# STM32H7B0x register map
File version: 1.3
CPU: CM7 r0p1, little endian, MPU, FPU, 4 interrupt priority bits
Registers are 32-bit, read-write, reset 0x0 unless marked. A register's access mark holds for its fields unless they carry their own. Offsets are from the block's base; [hi:lo] are bit positions; 'fields as' and 'values as' point back to an identical list.

## RTC
Base 0x58004000
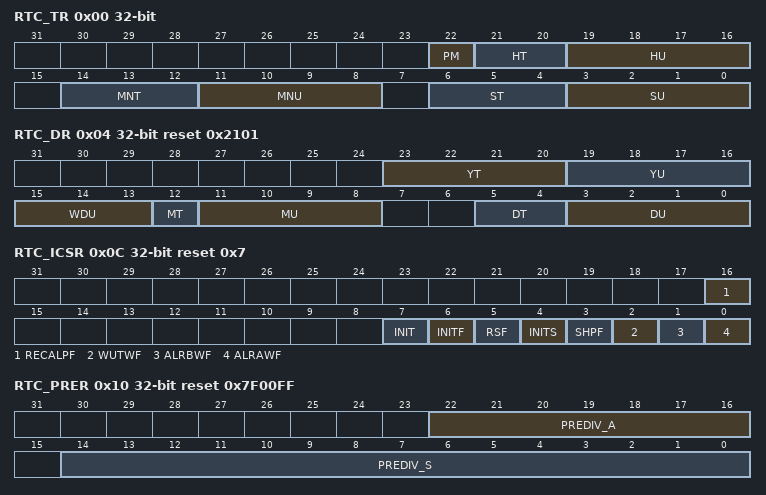
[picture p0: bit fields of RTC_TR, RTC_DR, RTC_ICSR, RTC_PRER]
0x00 RTC_TR — RTC time register
  [22] PM — AM/PM notation
    0=AM or 24-hour format; 1=PM
  [21:20] HT — Hour tens in BCD format
  [19:16] HU — Hour units in BCD format
  [14:12] MNT — Minute tens in BCD format
  [11:8] MNU — Minute units in BCD format
  [6:4] ST — Second tens in BCD format
  [3:0] SU — Second units in BCD format
0x04 RTC_DR reset 0x2101 — RTC date register
  [23:20] YT — Year tens in BCD format
  [19:16] YU — Year units in BCD format
  [15:13] WDU — Week day units ...
    0=forbidden; 1=Monday; 7=Sunday
  [12] MT — Month tens in BCD format
  [11:8] MU — Month units in BCD format
  [5:4] DT — Date tens in BCD format
  [3:0] DU — Date units in BCD format
0x08 RTC_SSR ro — RTC sub second register
  [15:0] SS — Sub second value SS[15:0] is the value in the synchronous prescaler counter. The fraction of a second is given by the formula below: Second fraction = (PREDIV_S - SS) / (PREDIV_S + 1) Note: SS can be larger than PREDIV_S only after a shift operation. In that case, the correct time/date is one second less than as indicated by RTC_TR/RTC_DR.
0x0C RTC_ICSR access per field reset 0x7 — RTC initialization control and status register
  [16] RECALPF ro — Recalibration pending Flag The RECALPF status flag is automatically set to 1 when software writes to the RTC_CALR register, indicating that the RTC_CALR register is blocked. When the new calibration settings are taken into account, this bit returns to 0. Refer to .
  [7] INIT rw — Initialization mode
    0=Free running mode; 1=Initialization mode used to program time and date register (RTC_TR and RTC_DR), and prescaler register (RTC_PRER). Counters are stopped and start counting from the new value when INIT is reset.
  [6] INITF ro — Initialization flag When this bit is set to 1, the RTC is in initialization state, and the time, date and prescaler registers can be updated.
    0=Calendar registers update is not allowed; 1=Calendar registers update is allowed
  [5] RSF rw — Registers synchronization flag This bit is set by hardware each time the calendar registers are copied into the shadow registers (RTC_SSRx, RTC_TRx and RTC_DRx). This bit is cleared by hardware in initialization mode, while a shift operation is pending (SHPF = 1), or when in bypass shadow register mode (BYPSHAD = 1). This bit can also be cleared by software. It is cleared either by software or by hardware in initialization mode.
    0=Calendar shadow registers not yet synchronized; 1=Calendar shadow registers synchronized
  [4] INITS ro — Initialization status flag This bit is set by hardware when the calendar year field is different from 0 (Backup domain reset state).
    0=Calendar has not been initialized; 1=Calendar has been initialized
  [3] SHPF ro — Shift operation pending This flag is set by hardware as soon as a shift operation is initiated by a write to the RTC_SHIFTR register. It is cleared by hardware when the corresponding shift operation has been executed. Writing to the SHPF bit has no effect.
    0=No shift operation is pending; 1=A shift operation is pending
  [2] WUTWF ro — Wakeup timer write flag This bit is set by hardware when WUT value can be changed, after the WUTE bit has been set to 0 in RTC_CR. It is cleared by hardware in initialization mode.
    0=Wakeup timer configuration update not allowed except in initialization mode; 1=Wakeup timer configuration update allowed
  [1] ALRBWF ro — Alarm B write flag This bit is set by hardware when alarm B values can be changed, after the ALRBE bit has been set to 0 in RTC_CR. It is cleared by hardware in initialization mode.
    0=Alarm B update not allowed; 1=Alarm B update allowed
  [0] ALRAWF ro — Alarm A write flag This bit is set by hardware when alarm A values can be changed, after the ALRAE bit has been set to 0 in RTC_CR. It is cleared by hardware in initialization mode.
    0=Alarm A update not allowed; 1=Alarm A update allowed
0x10 RTC_PRER reset 0x7F00FF — RTC prescaler register
  [22:16] PREDIV_A — Asynchronous prescaler factor This is the asynchronous division factor: ck_apre frequency = RTCCLK frequency/(PREDIV_A+1)
  [14:0] PREDIV_S — Synchronous prescaler factor This is the synchronous division factor: ck_spre frequency = ck_apre frequency/(PREDIV_S+1)
0x14 RTC_WUTR reset 0xFFFF — RTC wakeup timer register
  [15:0] WUT — Wakeup auto-reload value bits When the wakeup timer is enabled (WUTE set to 1), the WUTF flag is set every (WUT[15:0]Â +Â 1) ck_wut cycles. The ck_wut period is selected through WUCKSEL[2:0] bits of the RTC_CR register. When WUCKSEL[2] = 1, the wakeup timer becomes 17-bits and WUCKSEL[1] effectively becomes WUT[16] the most-significant bit to be reloaded into the timer. The first assertion of WUTF occurs between WUT and (WUT + 1) ck_wut cycles after WUTE is set. Setting WUT[15:0] to 0x0000 with WUCKSEL[2:0] = 011 (RTCCLK/2) is forbidden.
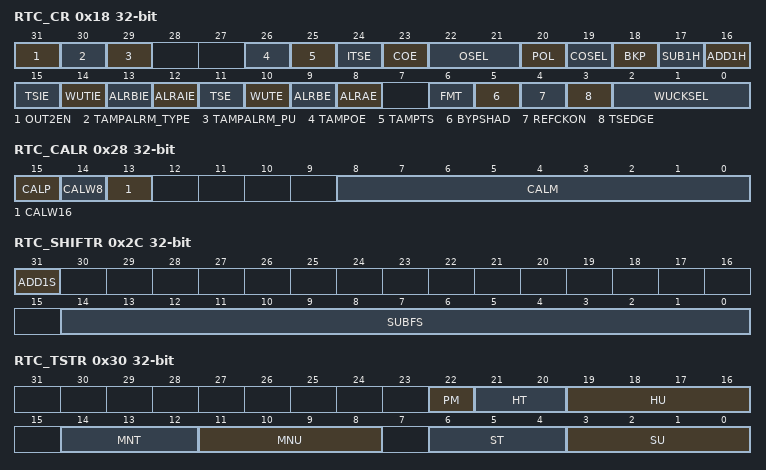
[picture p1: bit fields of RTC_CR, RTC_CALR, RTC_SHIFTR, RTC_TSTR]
0x18 RTC_CR access per field — RTC control register
  [31] OUT2EN rw — RTC_OUT2 output enable Setting this bit allows to remap the RTC outputs on RTC_OUT2 as follows: OUT2EN = 0: RTC output 2 disable If OSEL â 00 or TAMPOE = 1: TAMPALRM is output on RTC_OUT1 If OSEL = 00 and TAMPOE = 0 and COE = 1: CALIB is output on RTC_OUT1 OUT2EN = 1: RTC output 2 enable If (OSEL â 00 or TAMPOE = 1) and COE = 0: TAMPALRM is output on RTC_OUT2 If OSEL = 00 and TAMPOE = 0 and COE = 1: CALIB is output on RTC_OUT2 If (OSELâ 00 or TAMPOE = 1) and COE = 1: CALIB is output on RTC_OUT2 and TAMPALRM is output on RTC_OUT1.
  [30] TAMPALRM_TYPE rw — TAMPALRM output type
    0=TAMPALRM is push-pull output; 1=TAMPALRM is open-drain output
  [29] TAMPALRM_PU rw — TAMPALRM pull-up enable
    0=No pull-up is applied on TAMPALRM output; 1=A pull-up is applied on TAMPALRM output
  [26] TAMPOE rw — Tamper detection output enable on TAMPALRM
    0=The tamper flag is not routed on TAMPALRM; 1=The tamper flag is routed on TAMPALRM, combined with the signal provided by OSEL and with the polarity provided by POL
  [25] TAMPTS rw — Activate timestamp on tamper detection event TAMPTS is valid even if TSE = 0 in the RTC_CR register. Timestamp flag is set after the tamper flags, therefore if TAMPTS and TSIE are set, it is recommended to disable the tamper interrupts in order to avoid servicing 2 interrupts.
    0=Tamper detection event does not cause a RTC timestamp to be saved; 1=Save RTC timestamp on tamper detection event
  [24] ITSE rw — timestamp on internal event enable
    0=internal event timestamp disabled; 1=internal event timestamp enabled
  [23] COE rw — Calibration output enable This bit enables the CALIB output
    0=Calibration output disabled; 1=Calibration output enabled
  [22:21] OSEL rw — Output selection These bits are used to select the flag to be routed to TAMPALRM output.
    0=Output disabled; 1=Alarm A output enabled; 2=Alarm B output enabled; 3=Wakeup output enabled
  [20] POL rw — Output polarity This bit is used to configure the polarity of TAMPALRM output.
    0=The pin is high when ALRAF/ALRBF/WUTF is asserted (depending on OSEL[1:0]), or when a TAMPxF/ITAMPxF is asserted (if TAMPOE = 1); 1=The pin is low when ALRAF/ALRBF/WUTF is asserted (depending on OSEL[1:0]), or when a TAMPxF/ITAMPxF is asserted (if TAMPOE = 1)
  [19] COSEL rw — Calibration output selection When COE = 1, this bit selects which signal is output on CALIB. These frequencies are valid for RTCCLK at 32.768Â kHz and prescalers at their default values (PREDIV_A = 127 and PREDIV_S = 255). Refer to .
    0=Calibration output is 512 Hz; 1=Calibration output is 1 Hz
  [18] BKP rw — Backup This bit can be written by the user to memorize whether the daylight saving time change has been performed or not.
  [17] SUB1H wo — Subtract 1 hour (winter time change) When this bit is set outside initialization mode, 1 hour is subtracted to the calendar time if the current hour is not 0. This bit is always read as 0. Setting this bit has no effect when current hour is 0.
    0=No effect; 1=Subtracts 1 hour to the current time. This can be used for winter time change.
  [16] ADD1H wo — Add 1 hour (summer time change) When this bit is set outside initialization mode, 1 hour is added to the calendar time. This bit is always read as 0.
    0=No effect; 1=Adds 1 hour to the current time. This can be used for summer time change
  [15] TSIE rw — Timestamp interrupt enable
    0=Timestamp interrupt disable; 1=Timestamp interrupt enable
  [14] WUTIE rw — Wakeup timer interrupt enable
    0=Wakeup timer interrupt disabled; 1=Wakeup timer interrupt enabled
  [13] ALRBIE rw — Alarm B interrupt enable
    0=Alarm B interrupt disable; 1=Alarm B interrupt enable
  [12] ALRAIE rw — Alarm A interrupt enable
    0=Alarm A interrupt disabled; 1=Alarm A interrupt enabled
  [11] TSE rw — timestamp enable
    0=timestamp disable; 1=timestamp enable
  [10] WUTE rw — Wakeup timer enable Note: When the wakeup timer is disabled, wait for WUTWF=1 before enabling it again.
    0=Wakeup timer disabled; 1=Wakeup timer enabled
  [9] ALRBE rw — Alarm B enable
    0=Alarm B disabled; 1=Alarm B enabled
  [8] ALRAE rw — Alarm A enable
    0=Alarm A disabled; 1=Alarm A enabled
  [6] FMT rw — Hour format
    0=24 hour/day format; 1=AM/PM hour format
  [5] BYPSHAD rw — Bypass the shadow registers Note: If the frequency of the APB1 clock is less than seven times the frequency of RTCCLK, BYPSHAD must be set to 1.
    0=Calendar values (when reading from RTC_SSR, RTC_TR, and RTC_DR) are taken from the shadow registers, which are updated once every two RTCCLK cycles; 1=Calendar values (when reading from RTC_SSR, RTC_TR, and RTC_DR) are taken directly from the calendar counters
  [4] REFCKON rw — RTC_REFIN reference clock detection enable (50 or 60Â Hz) Note: PREDIV_S must be 0x00FF.
    0=RTC_REFIN detection disabled; 1=RTC_REFIN detection enabled
  [3] TSEDGE rw — Timestamp event active edge TSE must be reset when TSEDGE is changed to avoid unwanted TSF setting.
    0=RTC_TS input rising edge generates a timestamp event; 1=RTC_TS input falling edge generates a timestamp event
  [2:0] WUCKSEL rw — ck_wut wakeup clock selection 10x: ck_spre (usually 1Â Hz) clock is selected 11x: ck_spre (usually 1Â Hz) clock is selected and 216Â is added to the WUT counter value
    0=RTC/16 clock is selected; 1=RTC/8 clock is selected; 2=RTC/4 clock is selected; 3=RTC/2 clock is selected
0x24 RTC_WPR wo — RTC write protection register
  [7:0] KEY — Write protection key This byte is written by software. Reading this byte always returns 0x00. Refer to for a description of how to unlock RTC register write protection.
0x28 RTC_CALR — RTC calibration register
  [15] CALP — Increase frequency of RTC by 488.5Â ppm This feature is intended to be used in conjunction with CALM, which lowers the frequency of the calendar with a fine resolution. if the input frequency is 32768Â Hz, the number of RTCCLK pulses added during a 32-second window is calculated as follows: (512 Ã CALP) - CALM. Refer to .
    0=No RTCCLK pulses are added; 1=One RTCCLK pulse is effectively inserted every 211 pulses (frequency increased by 488.5Â ppm)
  [14] CALW8 — Use an 8-second calibration cycle period When CALW8 is set to 1, the 8-second calibration cycle period is selected. Note: CALM[1:0] are stuck at 00 when CALW8 = 1. Refer to digital calibration.
  [13] CALW16 — Use a 16-second calibration cycle period When CALW16 is set to 1, the 16-second calibration cycle period is selected. This bit must not be set to 1 if CALW8 = 1. Note: CALM[0] is stuck at 0 when CALW16 = 1. Refer to calibration.
  [8:0] CALM — Calibration minus The frequency of the calendar is reduced by masking CALM out of 220 RTCCLK pulses (32 seconds if the input frequency is 32768Â Hz). This decreases the frequency of the calendar with a resolution of 0.9537Â ppm. To increase the frequency of the calendar, this feature should be used in conjunction with CALP. See .
0x2C RTC_SHIFTR wo — RTC shift control register
  [31] ADD1S — Add one second This bit is write only and is always read as zero. Writing to this bit has no effect when a shift operation is pending (when SHPF = 1, in RTC_ICSR). This function is intended to be used with SUBFS (see description below) in order to effectively add a fraction of a second to the clock in an atomic operation.
    0=No effect; 1=Add one second to the clock/calendar
  [14:0] SUBFS — Subtract a fraction of a second These bits are write only and is always read as zero. Writing to this bit has no effect when a shift operation is pending (when SHPF = 1, in RTC_ICSR). The value which is written to SUBFS is added to the synchronous prescaler counter. Since this counter counts down, this operation effectively subtracts from (delays) the clock by: Delay (seconds) = SUBFS / (PREDIV_S + 1) A fraction of a second can effectively be added to the clock (advancing the clock) when the ADD1S function is used in conjunction with SUBFS, effectively advancing the clock by: Advance (seconds) = (1 - (SUBFS / (PREDIV_S + 1))). Note: Writing to SUBFS causes RSF to be cleared. Software can then wait until RSF = 1 to be sure that the shadow registers have been updated with the shifted time.
0x30 RTC_TSTR ro — RTC timestamp time register
  [22] PM — AM/PM notation
    0=AM or 24-hour format; 1=PM
  [21:20] HT — Hour tens in BCD format.
  [19:16] HU — Hour units in BCD format.
  [14:12] MNT — Minute tens in BCD format.
  [11:8] MNU — Minute units in BCD format.
  [6:4] ST — Second tens in BCD format.
  [3:0] SU — Second units in BCD format.
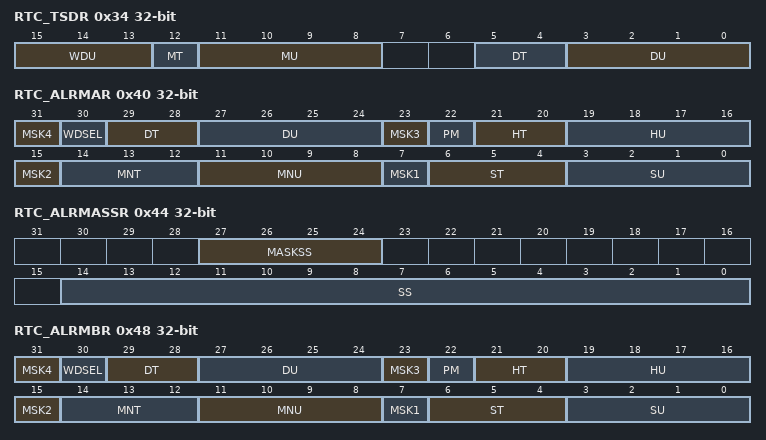
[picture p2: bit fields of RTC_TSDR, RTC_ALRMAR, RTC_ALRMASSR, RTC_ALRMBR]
0x34 RTC_TSDR ro — RTC timestamp date register
  [15:13] WDU — Week day units
  [12] MT — Month tens in BCD format
  [11:8] MU — Month units in BCD format
  [5:4] DT — Date tens in BCD format
  [3:0] DU — Date units in BCD format
0x38 RTC_TSSSR ro — RTC timestamp sub second register
  [15:0] SS — Sub second value SS[15:0] is the value of the synchronous prescaler counter when the timestamp event occurred.
0x40 RTC_ALRMAR — RTC alarm A register
  [31] MSK4 — Alarm A date mask
    0=Alarm A set if the date/day match; 1=Date/day don't care in alarm A comparison
  [30] WDSEL — Week day selection
    0=DU[3:0] represents the date units; 1=DU[3:0] represents the week day. DT[1:0] is don't care.
  [29:28] DT — Date tens in BCD format
  [27:24] DU — Date units or day in BCD format
  [23] MSK3 — Alarm A hours mask
    0=Alarm A set if the hours match; 1=Hours don't care in alarm A comparison
  [22] PM — AM/PM notation
    0=AM or 24-hour format; 1=PM
  [21:20] HT — Hour tens in BCD format
  [19:16] HU — Hour units in BCD format
  [15] MSK2 — Alarm A minutes mask
    0=Alarm A set if the minutes match; 1=Minutes don't care in alarm A comparison
  [14:12] MNT — Minute tens in BCD format
  [11:8] MNU — Minute units in BCD format
  [7] MSK1 — Alarm A seconds mask
    0=Alarm A set if the seconds match; 1=Seconds don't care in alarm A comparison
  [6:4] ST — Second tens in BCD format.
  [3:0] SU — Second units in BCD format.
0x44 RTC_ALRMASSR — RTC alarm A sub second register
  [27:24] MASKSS — Mask the most-significant bits starting at this bit 2: SS[14:2] are don't care in alarm A comparison. Only SS[1:0] are compared. 3: SS[14:3] are don't care in alarm A comparison. Only SS[2:0] are compared. ... 12: SS[14:12] are don't care in alarm A comparison. SS[11:0] are compared. 13: SS[14:13] are don't care in alarm A comparison. SS[12:0] are compared. 14: SS[14] is don't care in alarm A comparison. SS[13:0] are compared. 15: All 15 SS bits are compared and must match to activate alarm. The overflow bits of the synchronous counter (bits 15) is never compared. This bit can be different from 0 only after a shift operation. Note: The overflow bits of the synchronous counter (bits 15) is never compared. This bit can be different from 0 only after a shift operation.
    0=No comparison on sub seconds for alarm A. The alarm is set when the seconds unit is incremented (assuming that the rest of the fields match).; 1=SS[14:1] are don't care in alarm A comparison. Only SS[0] is compared.
  [14:0] SS — Sub seconds value This value is compared with the contents of the synchronous prescaler counter to determine if alarm A is to be activated. Only bits 0 up MASKSS-1 are compared.
0x48 RTC_ALRMBR — RTC alarm B register
  [31] MSK4 — Alarm B date mask
    0=Alarm B set if the date and day match; 1=Date and day don't care in alarm B comparison
  [30] WDSEL — Week day selection
    values as RTC_ALRMAR.WDSEL
  [29:28] DT — Date tens in BCD format
  [27:24] DU — Date units or day in BCD format
  [23] MSK3 — Alarm B hours mask
    0=Alarm B set if the hours match; 1=Hours don't care in alarm B comparison
  [22] PM — AM/PM notation
    0=AM or 24-hour format; 1=PM
  [21:20] HT — Hour tens in BCD format
  [19:16] HU — Hour units in BCD format
  [15] MSK2 — Alarm B minutes mask
    0=Alarm B set if the minutes match; 1=Minutes don't care in alarm B comparison
  [14:12] MNT — Minute tens in BCD format
  [11:8] MNU — Minute units in BCD format
  [7] MSK1 — Alarm B seconds mask
    0=Alarm B set if the seconds match; 1=Seconds don't care in alarm B comparison
  [6:4] ST — Second tens in BCD format
  [3:0] SU — Second units in BCD format
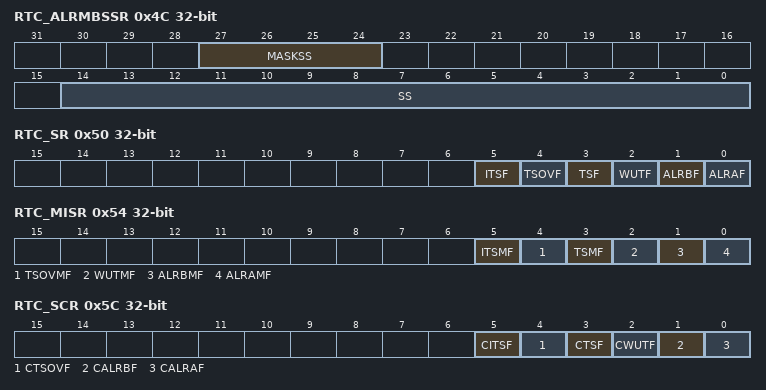
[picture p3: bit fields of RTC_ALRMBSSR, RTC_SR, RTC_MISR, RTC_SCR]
0x4C RTC_ALRMBSSR — RTC alarm B sub second register
  [27:24] MASKSS — Mask the most-significant bits starting at this bit ... The overflow bits of the synchronous counter (bits 15) is never compared. This bit can be different from 0 only after a shift operation.
    0=No comparison on sub seconds for alarm B. The alarm is set when the seconds unit is incremented (assuming that the rest of the fields match).; 1=SS[14:1] are don't care in alarm B comparison. Only SS[0] is compared.; 2=SS[14:2] are don't care in alarm B comparison. Only SS[1:0] are compared.; 3=SS[14:3] are don't care in alarm B comparison. Only SS[2:0] are compared.; 12=SS[14:12] are don't care in alarm B comparison. SS[11:0] are compared.; 13=SS[14:13] are don't care in alarm B comparison. SS[12:0] are compared.; 14=SS[14] is don't care in alarm B comparison. SS[13:0] are compared.; 15=All 15 SS bits are compared and must match to activate alarm
  [14:0] SS — Sub seconds value This value is compared with the contents of the synchronous prescaler counter to determine if alarm B is to be activated. Only bits 0 up to MASKSS-1 are compared.
0x50 RTC_SR ro — RTC status register
  [5] ITSF — Internal timestamp flag This flag is set by hardware when a timestamp on the internal event occurs.
  [4] TSOVF — Timestamp overflow flag This flag is set by hardware when a timestamp event occurs while TSF is already set. It is recommended to check and then clear TSOVF only after clearing the TSF bit. Otherwise, an overflow might not be noticed if a timestamp event occurs immediately before the TSF bit is cleared.
  [3] TSF — Timestamp flag This flag is set by hardware when a timestamp event occurs. If ITSF flag is set, TSF must be cleared together with ITSF.
  [2] WUTF — Wakeup timer flag This flag is set by hardware when the wakeup auto-reload counter reaches 0. This flag must be cleared by software at least 1.5 RTCCLK periods before WUTF is set to 1 again.
  [1] ALRBF — Alarm B flag This flag is set by hardware when the time/date registers (RTC_TR and RTC_DR) match the alarm B register (RTC_ALRMBR).
  [0] ALRAF — Alarm A flag This flag is set by hardware when the time/date registers (RTC_TR and RTC_DR) match the alarm A register (RTC_ALRMAR).
0x54 RTC_MISR ro — RTC masked interrupt status register
  [5] ITSMF — Internal timestamp masked flag This flag is set by hardware when a timestamp on the internal event occurs and timestampinterrupt is raised.
  [4] TSOVMF — Timestamp overflow masked flag This flag is set by hardware when a timestamp interrupt occurs while TSMF is already set. It is recommended to check and then clear TSOVF only after clearing the TSF bit. Otherwise, an overflow might not be noticed if a timestamp event occurs immediately before the TSF bit is cleared.
  [3] TSMF — Timestamp masked flag This flag is set by hardware when a timestamp interrupt occurs. If ITSF flag is set, TSF must be cleared together with ITSF.
  [2] WUTMF — Wakeup timer masked flag This flag is set by hardware when the wakeup timer interrupt occurs. This flag must be cleared by software at least 1.5 RTCCLK periods before WUTF is set to 1 again.
  [1] ALRBMF — Alarm B masked flag This flag is set by hardware when the alarm B interrupt occurs.
  [0] ALRAMF — Alarm A masked flag This flag is set by hardware when the alarm A interrupt occurs.
0x5C RTC_SCR wo — RTC status clear register
  [5] CITSF — Clear internal timestamp flag Writing 1 in this bit clears the ITSF bit in the RTC_SR register.
  [4] CTSOVF — Clear timestamp overflow flag Writing 1 in this bit clears the TSOVF bit in the RTC_SR register. It is recommended to check and then clear TSOVF only after clearing the TSF bit. Otherwise, an overflow might not be noticed if a timestamp event occurs immediately before the TSF bit is cleared.
  [3] CTSF — Clear timestamp flag Writing 1 in this bit clears the TSOVF bit in the RTC_SR register. If ITSF flag is set, TSF must be cleared together with ITSF by setting CRSF and CITSF.
  [2] CWUTF — Clear wakeup timer flag Writing 1 in this bit clears the WUTF bit in the RTC_SR register.
  [1] CALRBF — Clear alarm B flag Writing 1 in this bit clears the ALRBF bit in the RTC_SR register.
  [0] CALRAF — Clear alarm A flag Writing 1 in this bit clears the ALRBF bit in the RTC_SR register.
0x60 RTC_CFGR — RTC configuration register
  [0] OUT2_RMP — RTC_OUT2 mapping
    0=RTC_OUT2 is mapped on PB2; 1=RTC_OUT2 is mapped on PI8

## Notices in the file
Copyright (c) 2021 STMicroelectronics.
SPDX-License-Identifier: Apache-2.0
Licensed under the Apache License, Version 2.0 (the "License");
you may not use this file except in compliance with the License.
You may obtain a copy of the License at
http://www.apache.org/licenses/LICENSE-2.0
Unless required by applicable law or agreed to in writing, software
distributed under the License is distributed on an "AS IS" BASIS,
WITHOUT WARRANTIES OR CONDITIONS OF ANY KIND, either express or implied.
See the License for the specific language governing permissions and
limitations under the License.
